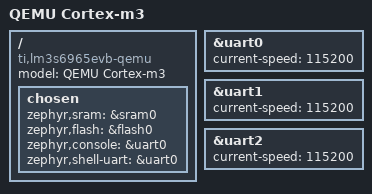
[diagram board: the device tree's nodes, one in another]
/dts-v1/;

#include <ti/lm3s6965.dtsi>

/ {
	model = "QEMU Cortex-m3";
	compatible = "ti,lm3s6965evb-qemu";

	chosen {
		zephyr,sram = &sram0;
		zephyr,flash = &flash0;
		zephyr,console = &uart0;
		zephyr,shell-uart = &uart0;
	};
};
&uart0 {
	status = "okay";
	current-speed = <115200>;
};

&uart1 {
	status = "okay";
	current-speed = <115200>;
};

&uart2 {
	status = "okay";
	current-speed = <115200>;
};
